# STM32WL31 register map
File version: 1.0
CPU: CM0+ r0p0, little endian, MPU, no FPU, 4 interrupt priority bits
Registers are 32-bit, read-write, reset 0x0 unless marked. A register's access mark holds for its fields unless they carry their own. Offsets are from the block's base; [hi:lo] are bit positions; {n}, {i} and the like mark numbered series.

## TIM2 — TIM2 address block description
Base 0x40002000
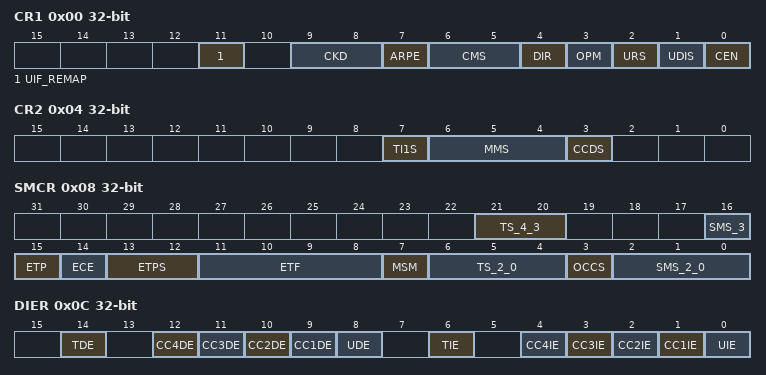
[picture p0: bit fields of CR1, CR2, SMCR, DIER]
0x00 CR1 (reset mask 0xF)
  [11] UIF_REMAP — UIFREMAP: UIF status bit remapping 0: No remapping. UIF status bit is not copied to TIMx_CNT register bit 31. 1: Remapping enabled. UIF status bit is copied to TIMx_CNT register bit 31.
  [9:8] CKD — CKD[1:0]: Clock division This bit-field indicates the division ratio between the timer clock (CK_INT) frequency and the dead-time and sampling clock (tDTS)used by the dead-time generators and the digital filters (TIx), 00: tDTS=tCK_INT 01: tDTS=2*tCK_INT 10: tDTS=4*tCK_INT 11: Reserved, do not program this value
  [7] ARPE — ARPE: Auto-reload preload enable 0: TIMx_ARR register is not buffered 1: TIMx_ARR register is buffered
  [6:5] CMS — CMS[1:0]: Center-aligned mode selection 00: Edge-aligned mode. The counter counts up or down depending on the direction bit (DIR). 01: Center-aligned mode 1. The counter counts up and down alternatively. Output compare interrupt flags of channels configured in output (CCxS=00 in TIMx_CCMRx register) are set only when the counter is counting down. 10: Center-aligned mode 2. The counter counts up and down alternatively. Output compare interrupt flags of channels configured in output (CCxS=00 in TIMx_CCMRx register) are set only when the counter is counting up. 11: Center-aligned mode 3. The counter counts up and down alternatively. Output compare interrupt flags of channels configured in output (CCxS=00 in TIMx_CCMRx register) are set both when the counter is counting up or down. Note: It is not allowed to switch from edge-aligned mode to center-aligned mode as long as the counter is enabled (CEN=1)
  [4] DIR — DIR: Direction 0: Counter used as upcounter 1: Counter used as downcounter Note: This bit is read only when the timer is configured in Center-aligned mode or Encoder mode.
  [3] OPM — OPM: One pulse mode 0: Counter is not stopped at update event. 1: Counter stops counting at the next update event (clearing the bit CEN)
  [2] URS — URS: Update request source This bit is set and cleared by software to select the UEV event sources. 0: Any of the following events generate an update interrupt or DMA request if enabled. These events can be: - Counter overflow/underflow - Setting the UG bit - Update generation through the slave mode controller 1: Only counter overflow/underflow generates an update interrupt or DMA request if enabled.
  [1] UDIS — UDIS: Update disable This bit is set and cleared by software to enable/disable UEV event generation. 0: UEV enabled. The Update (UEV) event is generated by one of the following events: - Counter overflow/underflow - Setting the UG bit - Update generation through the slave mode controller Buffered registers are then loaded with their preload values. 1: UEV disabled. The Update event is not generated, shadow registers keep their value (ARR, PSC, CCRx). However the counter and the prescaler are reinitialized if the UG bit is set or if a hardware reset is received from the slave mode controller.
  [0] CEN — CEN: Counter enable 0: Counter disabled 1: Counter enabled Note: External clock and gated mode can work only if the CEN bit has been previously set by software. However trigger mode can set the CEN bit automatically by hardware.
0x04 CR2 (reset mask 0xF)
  [7] TI1S — TI1S: TI1 selection 0: The TIMx_CH1 pin is connected to TI1 input. 1: The TIMx_CH1, CH2 and CH3 pins are connected to the TI1 input (XOR combination)
  [6:4] MMS — MMS[2:0]: Master mode selection These bits allow to select the information to be sent in master mode to slave timers for synchronization (TRGO). The combination is as follows: 000: Reset - the UG bit from the TIMx_EGR register is used as trigger output (TRGO). If the reset is generated by the trigger input (slave mode controller configured in reset mode) then the signal on TRGO is delayed compared to the actual reset. 001: Enable - the Counter enable signal, CNT_EN, is used as trigger output (TRGO). It is useful to start several timers at the same time or to control a window in which a slave timer is enabled. The Counter Enable signal is generated by a logic OR between CEN control bit and the trigger input when configured in gated mode. When the Counter Enable signal is controlled by the trigger input, there is a delay on TRGO, except if the master/slave mode is selected (see the MSM bit description in TIMx_SMCR register). 010: Update - The update event is selected as trigger output (TRGO). For instance a master timer can then be used as a prescaler for a slave timer. 011: Compare Pulse - The trigger output send a positive pulse when the CC1IF flag is to be set (even if it was already high), as soon as a capture or a compare match occurred. (TRGO) 100: Compare - OC1REF signal is used as trigger output (TRGO) 101: Compare - OC2REF signal is used as trigger output (TRGO) 110: Compare - OC3REF signal is used as trigger output (TRGO) 111: Compare - OC4REF signal is used as trigger output (TRGO) Note: The clock of the slave timer must be enabled prior to receive events from the master timer, and must not be changed on-the-fly while triggers are received from the master timer.
  [3] CCDS — CCDS: Capture/compare DMA selection 0: CCx DMA request sent when CCx event occurs 1: CCx DMA requests sent when update event occurs
0x08 SMCR reset not defined
  [21:20] TS_4_3 — Trigger selection. See TS_2_0_ description
  [16] SMS_3 — SMS[3]: Slave mode selection - bit 3 Refer to SMS description - bits2:0
  [15] ETP — ETP: External trigger polarity This bit selects whether ETR or ETR is used for trigger operations 0: ETR is non-inverted, active at high level or rising edge. 1: ETR is inverted, active at low level or falling edge.
  [14] ECE — ECE: External clock enable This bit enables External clock mode 2. 0: External clock mode 2 disabled 1: External clock mode 2 enabled. The counter is clocked by any active edge on the ETRF signal. Note: 1: Setting the ECE bit has the same effect as selecting external clock mode 1 with TRGI connected to ETRF (SMS=111 and TS=111). Note: 2: It is possible to simultaneously use external clock mode 2 with the following slave modes: reset mode, gated mode and trigger mode. Nevertheless, TRGI must not be connected to ETRF in this case (TS bits must not be 111). Note: 3: If external clock mode 1 and external clock mode 2 are enabled at the same time, the external clock input is ETRF.
  [13:12] ETPS — ETPS[1:0]: External trigger prescaler External trigger signal ETRP frequency must be at most 1/4 of TIMxCLK frequency. A prescaler can be enabled to reduce ETRP frequency. It is useful when inputting fast external clocks. 00: Prescaler OFF 01: ETRP frequency divided by 2 10: ETRP frequency divided by 4 11: ETRP frequency divided by 8
  [11:8] ETF — ETF[3:0]: External trigger filter This bit-field then defines the frequency used to sample ETRP signal and the length of the digital filter applied to ETRP. The digital filter is made of an event counter in which N events are needed to validate a transition on the output: 0000: No filter, sampling is done at fDTS 0001: fSAMPLING=fCK_INT, N=2 0010: fSAMPLING=fCK_INT, N=4 0011: fSAMPLING=fCK_INT, N=8 0100: fSAMPLING=fDTS/2, N=6 0101: fSAMPLING=fDTS/2, N=8 0110: fSAMPLING=fDTS/4, N=6 0111: fSAMPLING=fDTS/4, N=8 1000: fSAMPLING=fDTS/8, N=6 1001: fSAMPLING=fDTS/8, N=8 1010: fSAMPLING=fDTS/16, N=5 1011: fSAMPLING=fDTS/16, N=6 1100: fSAMPLING=fDTS/16, N=8 1101: fSAMPLING=fDTS/32, N=5 1110: fSAMPLING=fDTS/32, N=6 1111: fSAMPLING=fDTS/32, N=8
  [7] MSM — MSM: Master/Slave mode 0: No action 1: The effect of an event on the trigger input (TRGI) is delayed to allow a perfect synchronization between the current timer and its slaves (through TRGO). It is useful if we want to synchronize several timers on a single external event.
  [6:4] TS_2_0 — TS[4:0]: Trigger selection This bit-field selects the trigger input to be used to synchronize the counter. 00000: Internal Trigger 0 (ITR0) 00001: Internal Trigger 1 (ITR1) 00010: Internal Trigger 2 (ITR2) 00011: Internal Trigger 3 (ITR3) 00100: TI1 Edge Detector (TI1F_ED) 00101: Filtered Timer Input 1 (TI1FP1) 00110: Filtered Timer Input 2 (TI2FP2) 00111: External Trigger input (ETRF) Others: Reserved See Table Note:: TIM2 internal trigger connection on page 395 for more details on ITRx meaning for each Timer. Note: These bits must be changed only when they are not used (e.g. when SMS=000) to avoid wrong edge detections at the transition.
  [3] OCCS — OCCS: OCREF clear selection This bit is used to select the OCREF clear source. 0: OCREF_CLR_INT is connected to the OCREF_CLR input (stuck at 0 so no effect) 1: OCREF_CLR_INT is connected to ETRF
  [2:0] SMS_2_0 — SMS: Slave mode selection When external signals are selected the active edge of the trigger signal (TRGI) is linked to the polarity selected on the external input (see Input Control register and Control Register description. 0000: Slave mode disabled - if CEN = '1' then the prescaler is clocked directly by the internal clock. 0001: Encoder mode 1 - Counter counts up/down on TI2FP2 edge depending on TI1FP1 level. 0010: Encoder mode 2 - Counter counts up/down on TI1FP1 edge depending on TI2FP2 level. 0011: Encoder mode 3 - Counter counts up/down on both TI1FP1 and TI2FP2 edges depending on the level of the other input. 0100: Reset Mode - Rising edge of the selected trigger input (TRGI) reinitializes the counter and generates an update of the registers. 0101: Gated Mode - The counter clock is enabled when the trigger input (TRGI) is high. The counter stops (but is not reset) as soon as the trigger becomes low. Both start and stop of the counter are controlled. 0110: Trigger Mode - The counter starts at a rising edge of the trigger TRGI (but it is not reset). Only the start of the counter is controlled. 0111: External Clock Mode 1 - Rising edges of the selected trigger (TRGI) clock the counter. 1000: Combined reset + trigger mode - Rising edge of the selected trigger input (TRGI) reinitializes the counter, generates an update of the registers and starts the counter. Codes above 1000: Reserved. Note: The gated mode must not be used if TI1F_ED is selected as the trigger input (TS='100'). Indeed, TI1F_ED outputs 1 pulse for each transition on TI1F, whereas the gated mode checks the level of the trigger signal.
0x0C DIER (reset mask 0xF)
  [14] TDE — TDE: Trigger DMA request enable 0: Trigger DMA request disabled 1: Trigger DMA request enabled
  [n+8] CC{n}DE (n=1..4) — CC{n}DE: Capture/Compare {n} DMA request enable 0: CC{n} DMA request disabled 1: CC{n} DMA request enabled
  [8] UDE — UDE: Update DMA request enable 0: Update DMA request disabled 1: Update DMA request enabled
  [6] TIE — TIE: Trigger interrupt enable 0: Trigger interrupt disabled 1: Trigger interrupt enabled
  [4] CC4IE — CC4IE: Capture/Compare 4 interrupt enable 0: CC4 interrupt disabled 1: CC4 interrupt enabled
  [3] CC3IE — CC3IE: Capture/Compare 3 interrupt enable 0: CC3 interrupt disabled 1: CC3 interrupt enabled
  [2] CC2IE — CC2IE: Capture/Compare 2 interrupt enable 0: CC2 interrupt disabled 1: CC2 interrupt enabled
  [1] CC1IE — CC1IE: Capture/Compare 1 interrupt enable 0: CC1 interrupt disabled. 1: CC1 interrupt enabled
  [0] UIE — UIE: Update interrupt enable 0: Update interrupt disabled 1: Update interrupt enabled
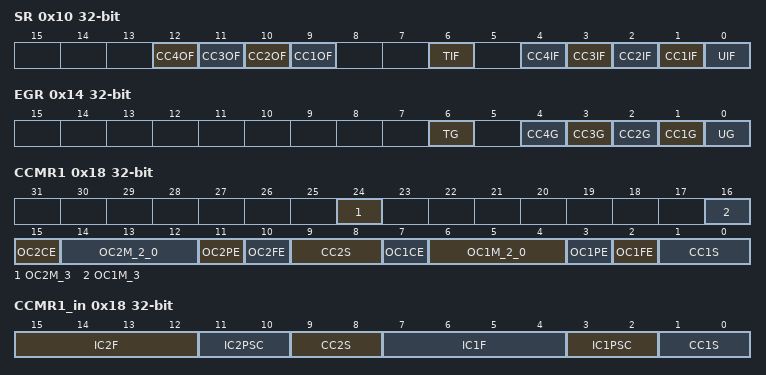
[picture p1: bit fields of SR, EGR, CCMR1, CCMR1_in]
0x10 SR (reset mask 0xF)
  [12] CC4OF — CC4OF: Capture/Compare 4 overcapture flag refer to CC1OF description
  [11] CC3OF — CC3OF: Capture/Compare 3 overcapture flag refer to CC1OF description
  [10] CC2OF — CC2OF: Capture/Compare 2 overcapture flag refer to CC1OF description
  [9] CC1OF — CC1OF: Capture/Compare 1 overcapture flag This flag is set by hardware only when the corresponding channel is configured in input capture mode. It is cleared by software by writing it to '0'. 0: No overcapture has been detected 1: The counter value has been captured in TIMx_CCR1 register while CC1IF flag was already set
  [6] TIF — TIF: Trigger interrupt flag This flag is set by hardware on trigger event (active edge detected on TRGI input when the slave mode controller is enabled in all modes but gated mode. It is set when the counter starts or stops when gated mode is selected. It is cleared by software.. 0: No trigger event occurred. 1: Trigger interrupt pending.
  [4] CC4IF — CC4IF: Capture/Compare 4 interrupt flag refer to CC1IF description
  [3] CC3IF — CC3IF: Capture/Compare 3 interrupt flag refer to CC1IF description
  [2] CC2IF — CC2IF: Capture/Compare 2 interrupt flag refer to CC1IF description
  [1] CC1IF — CC1IF: Capture/Compare 1 interrupt flag If channel CC1 is configured as output: This flag is set by hardware when the counter matches the compare value, with some exception in center-aligned mode (refer to the CMS bits in the TIMx_CR1 register description). It is cleared by software. 0: No match. 1: The content of the counter TIMx_CNT matches the content of the TIMx_CCR1 register. When the contents of TIMx_CCR1 are greater than the contents of TIMx_ARR, the CC1IF bit goes high on the counter overflow (in upcounting and up/down-counting modes) or underflow (in downcounting mode) If channel CC1 is configured as input: This bit is set by hardware on a capture. It is cleared by software or by reading the TIMx_CCR1 register. 0: No input capture occurred 1: The counter value has been captured in TIMx_CCR1 register (An edge has been detected on IC1 which matches the selected polarity)
  [0] UIF — UIF: Update interrupt flag This bit is set by hardware on an update event. It is cleared by software. 0: No update occurred. 1: Update interrupt pending. This bit is set by hardware when the registers are updated: At overflow regarding the repetition counter value (update if repetition counter = 0) and if the UDIS=0 in the TIMx_CR1 register. When CNT is reinitialized by software using the UG bit in TIMx_EGR register, if URS=0 and UDIS=0 in the TIMx_CR1 register.
0x14 EGR (reset mask 0xF)
  [6] TG wo — TG: Trigger generation This bit is set by software in order to generate an event, it is automatically cleared by hardware. 0: No action 1: The TIF flag is set in TIMx_SR register. Related interrupt can occur if enabled.
  [4] CC4G wo — CC4G: Capture/Compare 4 generation refer to CC1G description
  [3] CC3G wo — CC3G: Capture/Compare 3 generation refer to CC1G description
  [2] CC2G wo — CC2G: Capture/Compare 2 generation refer to CC1G description
  [1] CC1G wo — CC1G: Capture/Compare 1 generation This bit is set by software in order to generate an event, it is automatically cleared by hardware. 0: No action. 1: A capture/compare event is generated on channel 1: If channel CC1 is configured as output: CC1IF flag is set, Corresponding interrupt or DMA request is sent if enabled. If channel CC1 is configured as input: The current value of the counter is captured in TIMx_CCR1 register. The CC1IF flag is set, the corresponding interrupt or DMA request is sent if enabled. The CC1OF flag is set if the CC1IF flag was already high.
  [0] UG wo — UG: Update generation This bit can be set by software, it is automatically cleared by hardware. 0: No action. 1: Reinitialize the counter and generates an update of the registers. Note that the prescaler counter is cleared too (anyway the prescaler ratio is not affected).
0x18 CCMR1 (reset mask 0xF)
  [24] OC2M_3 — OC2M[3]: Output Compare 2 mode (bit 3)
  [16] OC1M_3 — OC1M[3]: Output Compare 1 mode (bit 3)
  [15] OC2CE — OC2CE: Output Compare 2 clear enable
  [14:12] OC2M_2_0 — OC2M[2:0]: Output Compare 2 mode
  [11] OC2PE — OC2PE: Output Compare 2 preload enable
  [10] OC2FE — OC2FE: Output Compare 2 fast enable
  [9:8] CC2S — CC2S[1:0]: Capture/Compare 2 selection This bit-field defines the direction of the channel (input/output) as well as the used input. 00: CC2 channel is configured as output 01: CC2 channel is configured as input, IC2 is mapped on TI2 10: CC2 channel is configured as input, IC2 is mapped on TI1 11: CC2 channel is configured as input, IC2 is mapped on TRC. This mode is working only if an internal trigger input is selected through the TS bit (TIMx_SMCR register) Note: CC2S bits are writable only when the channel is OFF (CC2E = '0' in TIMx_CCER).
  [7] OC1CE — OC1CE: Output Compare 1 Clear Enable 0: OC1Ref is not affected by the ETRF Input 1: OC1Ref is cleared as soon as a High level is detected on ETRF input
  [6:4] OC1M_2_0 — OC1M: Output Compare 1 mode These bits define the behavior of the output reference signal OC1REF from which OC1 and OC1N are derived. OC1REF is active high whereas OC1 and OC1N active level depends on CC1P and CC1NP bits. 0000: Frozen - The comparison between the output compare register TIMx_CCR1 and the counter TIMx_CNT has no effect on the outputs.(this mode is used to generate a timing base). 0001: Set channel 1 to active level on match. OC1REF signal is forced high when the counter TIMx_CNT matches the capture/compare register 1 (TIMx_CCR1). 0010: Set channel 1 to inactive level on match. OC1REF signal is forced low when the counter TIMx_CNT matches the capture/compare register 1 (TIMx_CCR1). 0011: Toggle - OC1REF toggles when TIMx_CNT=TIMx_CCR1. 0100: Force inactive level - OC1REF is forced low. 0101: Force active level - OC1REF is forced high. 0110: PWM mode 1 - In upcounting, channel 1 is active as long as TIMx_CNT TIMx_CCR1 else inactive. In downcounting, channel 1 is inactive (OC1REF='0') as long as TIMx_CNT>TIMx_CCR1 else active (OC1REF='1'). 0111: PWM mode 2 - In upcounting, channel 1 is inactive as long as TIMx_CNT TIMx_CCR1 else active. In downcounting, channel 1 is active as long as TIMx_CNT>TIMx_CCR1 else inactive. 1000: Retrigerrable OPM mode 1 - In up-counting mode, the channel is active until a trigger event is detected (on TRGI signal). Then, a comparison is performed as in PWM mode 1 and the channels becomes active again at the next update. In down-counting mode, the channel is inactive until a trigger event is detected (on TRGI signal). Then, a comparison is performed as in PWM mode 1 and the channels becomes inactive again at the next update. 1001: Retrigerrable OPM mode 2 - In up-counting mode, the channel is inactive until a trigger event is detected (on TRGI signal). Then, a comparison is performed as in PWM mode 2 and the channels becomes inactive again at the next update. In down-counting mode, the channel is active until a trigger event is detected (on TRGI signal). Then, a comparison is performed as in PWM mode 1 and the channels becomes active again at the next update. 1010: Reserved 1011: Reserved 1100: Combined PWM mode 1 - OC1REF has the same behavior as in PWM mode 1. OC1REFC is the logical OR between OC1REF and OC2REF. 1101: Combined PWM mode 2 - OC1REF has the same behavior as in PWM mode 2. OC1REFC is the logical AND between OC1REF and OC2REF 1110: Asymmetric PWM mode 1 - OC1REF has the same behavior as in PWM mode 1. OC1REFC outputs OC1REF when the counter is counting up, OC2REF when it is counting down. 1111: Asymmetric PWM mode 2 - OC1REF has the same behavior as in PWM mode 2. OC1REFC outputs OC1REF when the counter is counting up, OC2REF when it is counting down. Note: 1: These bits can not be modified as long as LOCK level 3 has been programmed (LOCK bits in TIMx_BDTR register) and CC1S='00' (the channel is configured in output). Note: 2: In PWM mode, the OCREF level changes only when the result of the comparison changes or when the output compare mode switches from 'frozen' mode to 'PWM' mode.
  [3] OC1PE — OC1PE: Output Compare 1 preload enable 0: Preload register on TIMx_CCR1 disabled. TIMx_CCR1 can be written at anytime, the new value is taken in account immediately. 1: Preload register on TIMx_CCR1 enabled. Read/Write operations access the preload register. TIMx_CCR1 preload value is loaded in the active register at each update event. Note: 1: These bits can not be modified as long as LOCK level 3 has been programmed (LOCK bits in TIMx_BDTR register) and CC1S='00' (the channel is configured in output). Note: 2: The PWM mode can be used without validating the preload register only in one pulse mode (OPM bit set in TIMx_CR1 register). Else the behavior is not guaranteed.
  [2] OC1FE — OC1FE: Output Compare 1 fast enable This bit is used to accelerate the effect of an event on the trigger in input on the CC output. 0: CC1 behaves normally depending on counter and CCR1 values even when the trigger is ON. The minimum delay to activate CC1 output when an edge occurs on the trigger input is 5 clock cycles. 1: An active edge on the trigger input acts like a compare match on CC1 output. Then, OC is set to the compare level independently of the result of the comparison. Delay to sample the trigger input and to activate CC1 output is reduced to 3 clock cycles. OC1FE acts only if the channel is configured in PWM1 or PWM2 mode.
  [1:0] CC1S — CC1S: Capture/Compare 1 Selection This bit-field defines the direction of the channel (input/output) as well as the used input. 00: CC1 channel is configured as output 01: CC1 channel is configured as input, IC1 is mapped on TI1 1x: Reserved Note: CC1S bits are writable only when the channel is OFF (CC1E = '0' in TIMx_CCER).
0x18 CCMR1_in (reset mask 0xF) (alternate view of CCMR1)
  [15:12] IC2F — IC2F: Input capture 2 filter
  [11:10] IC2PSC — IC2PSC[1:0]: Input capture 2 prescaler
  [9:8] CC2S — CC2S: Capture/Compare 2 selection This bit-field defines the direction of the channel (input/output) as well as the used input. 00: CC2 channel is configured as output 01: CC2 channel is configured as input, IC2 is mapped on TI2 10: CC2 channel is configured as input, IC2 is mapped on TI1 11: CC2 channel is configured as input, IC2 is mapped on TRC. This mode is working only if an internal trigger input is selected through TS bit (TIMx_SMCR register) Note: CC2S bits are writable only when the channel is OFF (CC2E = '0' in TIMx_CCER).
  [7:4] IC1F — Bits 7:4 IC1F[3:0]: Input capture 1 filter This bit-field defines the frequency used to sample TI1 input and the length of the digital filter applied to TI1. The digital filter is made of an event counter in which N events are needed to validate a transition on the output: 0000: No filter, sampling is done at fDTS 0001: fSAMPLING=fCK_INT, N=2 0010: fSAMPLING=fCK_INT, N=4 0011: fSAMPLING=fCK_INT, N=8 0100: fSAMPLING=fDTS/2, N= 0101: fSAMPLING=fDTS/2, N=8 0110: fSAMPLING=fDTS/4, N=6 0111: fSAMPLING=fDTS/4, N=8 1000: fSAMPLING=fDTS/8, N=6 1001: fSAMPLING=fDTS/8, N=8 1010: fSAMPLING=fDTS/16, N=5 1011: fSAMPLING=fDTS/16, N=6 1100: fSAMPLING=fDTS/16, N=8 1101: fSAMPLING=fDTS/32, N=5 1110: fSAMPLING=fDTS/32, N=6 1111: fSAMPLING=fDTS/32, N=8
  [3:2] IC1PSC — IC1PSC: Input capture 1 prescaler This bit-field defines the ratio of the prescaler acting on CC1 input (IC1). The prescaler is reset as soon as CC1E='0' (TIMx_CCER register). 00: no prescaler, capture is done each time an edge is detected on the capture input. 01: capture is done once every 2 events 10: capture is done once every 4 events 11: capture is done once every 8 events
  [1:0] CC1S — CC1S: Capture/Compare 1 Selection This bit-field defines the direction of the channel (input/output) as well as the used input. 00: CC1 channel is configured as output 01: CC1 channel is configured as input, IC1 is mapped on TI1 1x: Reserved Note: CC1S bits are writable only when the channel is OFF (CC1E = '0' in TIMx_CCER).
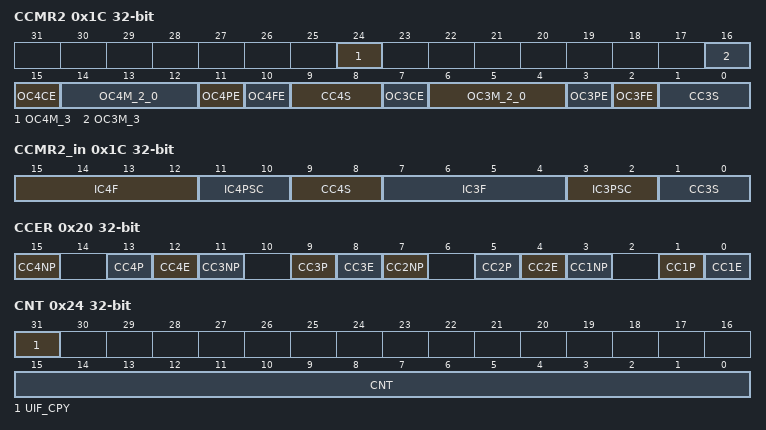
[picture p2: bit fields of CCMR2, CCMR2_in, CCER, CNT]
0x1C CCMR2 (reset mask 0xF)
  [24] OC4M_3 — OC4M[3]: Output Compare 4 mode (bit 3)
  [16] OC3M_3 — OC3M[3]: Output Compare 3 mode (bit 3)
  [15] OC4CE — OC4CE: Output Compare 4 clear enable
  [14:12] OC4M_2_0 — OC4M[2:0]: Output Compare 4 mode
  [11] OC4PE — OC4PE: Output Compare 4 preload enable
  [10] OC4FE — OC4FE: Output Compare 4 fast enable
  [9:8] CC4S — CC4S: Capture/Compare 4 selection This bit-field defines the direction of the channel (input/output) as well as the used input. 00: CC4 channel is configured as output 01: CC4 channel is configured as input, IC4 is mapped on TI4 10: CC4 channel is configured as input, IC4 is mapped on TI3 11: CC4 channel is configured as input, IC4 is mapped on TRC. This mode is working only if an internal trigger input is selected through TS bit (TIMx_SMCR register) Note: CC4S bits are writable only when the channel is OFF (CC4E = '0' in TIMx_CCER).
  [7] OC3CE — OC3CE: Output compare 3 clear enable
  [6:4] OC3M_2_0 — OC3M: Output compare 3 mode
  [3] OC3PE — OC3PE: Output compare 3 preload enable
  [2] OC3FE — OC3FE: Output compare 3 fast enable
  [1:0] CC3S — CC3S: Capture/Compare 3 selection This bit-field defines the direction of the channel (input/output) as well as the used input. 00: CC3 channel is configured as output 01: CC3 channel is configured as input, IC3 is mapped on TI3 10: CC3 channel is configured as input, IC3 is mapped on TI4 11: CC3 channel is configured as input, IC3 is mapped on TRC. This mode is working only if an internal trigger input is selected through TS bit (TIMx_SMCR register) Note: CC3S bits are writable only when the channel is OFF (CC3E = '0' in TIMx_CCER).
0x1C CCMR2_in (reset mask 0xF) (alternate view of CCMR2)
  [15:12] IC4F — IC4F: Input capture 4 filter
  [11:10] IC4PSC — IC4PSC: Input capture 4 prescaler
  [9:8] CC4S — CC4S: Capture/Compare 4 selection This bit-field defines the direction of the channel (input/output) as well as the used input. 00: CC4 channel is configured as output 01: CC4 channel is configured as input, IC4 is mapped on TI4 10: CC4 channel is configured as input, IC4 is mapped on TI3 11: CC4 channel is configured as input, IC4 is mapped on TRC. This mode is working only if an internal trigger input is selected through TS bit (TIMx_SMCR register) Note: CC4S bits are writable only when the channel is OFF (CC4E = '0' in TIMx_CCER).
  [7:4] IC3F — IC3F: Input capture 3 filter
  [3:2] IC3PSC — IC3PSC: Input capture 3 prescaler
  [1:0] CC3S — CC3S: Capture/compare 3 selection This bit-field defines the direction of the channel (input/output) as well as the used input. 00: CC3 channel is configured as output 01: CC3 channel is configured as input, IC3 is mapped on TI3 10: CC3 channel is configured as input, IC3 is mapped on TI4 11: CC3 channel is configured as input, IC3 is mapped on TRC. This mode is working only if an internal trigger input is selected through TS bit (TIMx_SMCR register) Note: CC3S bits are writable only when the channel is OFF (CC3E = '0' in TIMx_CCER).
0x20 CCER (reset mask 0xF)
  [15] CC4NP — CC4NP: Capture/Compare 4 Complementary output Polarity. This field is not used in Blue51. Not available in IUM refer to CC1NP description
  [13] CC4P — CC4P: Capture/Compare 4 output polarity refer to CC1P description
  [12] CC4E — CC4E: Capture/Compare 4 output enable refer to CC1E description
  [11] CC3NP — CC3NP: Capture/Compare 3 Complementary output Polarity. This field is not used in Blue51. Not available in IUM refer to CC1NP description
  [9] CC3P — CC3P: Capture/Compare 3 output polarity refer to CC1P description
  [8] CC3E — CC3E: Capture/Compare 3 output enable refer to CC1E description
  [7] CC2NP — CC2NP: Capture/Compare 2 Complementary output Polarity. This field is not used in Blue51. Not available in IUM refer to CC1NP description
  [5] CC2P — CC2P: Capture/Compare 2 output polarity refer to CC1P description
  [4] CC2E — CC2E: Capture/Compare 2 output enable refer to CC1E description
  [3] CC1NP — CC1NP: Capture/Compare 1 Complementary output Polarity. This field is not used in Blue51. Not available in IUM Note: This bit is no longer writeable as soon as LOCK level 2 or 3 has been programmed (LOCK bits in GPT_BDTR register) and CC1S='00' (the channel is configured in output).
    0=OC1N active high; 1=OC1N active low
  [1] CC1P — CC1P: Capture/Compare 1 output polarity CC1 channel configured as output: 0: OC1 active high 1: OC1 active low CC1 channel configured as input: The CC1NP/CC1P bits select the polarity of TI1FP1 for trigger or capture operations. 00: Non-inverted/rising edge. The circuit is sensitive to TIxFP1 rising edge (capture or trigger operations in reset, external clock or trigger mode), TIxFP1 is not inverted (trigger operation in gated mode). 01: Inverted/falling edge. The circuit is sensitive to TIxFP1 falling edge (capture or trigger operations in reset, external clock or trigger mode), TIxFP1 is inverted (trigger operation in gated mode. 10: Reserved, do not use this configuration. 11: Non-inverted/both edges. The circuit is sensitive to both TIxFP1 rising and falling edges (capture or trigger operations in reset, external clock or trigger mode), TIxFP1 is not inverted (trigger operation in gated mode). Note: 1. This bit is not writable as soon as LOCK level 2 or 3 has been programmed (LOCK bits in TIMx_BDTR register). 2. On channels that have a complementary output, this bit is preloaded. If the CCPC bit is set in the TIMx_CR2 register then the CC1P active bit takes the new value from the preloaded bit only when a Commutation event is generated.
  [0] CC1E — CC1E: Capture/Compare 1 output enable CC1 channel configured as output: 0: Off - OC1 is not active. OC1 level is then function of MOE, OSSI, OSSR, OIS1, OIS1N and CC1NE bits. 1: On - OC1 signal is output on the corresponding output pin depending on MOE, OSSI, OSSR, OIS1, OIS1N and CC1NE bits. CC1 channel configured as input: This bit determines if a capture of the counter value can actually be done into the input capture/compare register 1 (TIMx_CCR1) or not. 0: Capture disabled 1: Capture enabled
0x24 CNT (reset mask 0xF)
  [31] UIF_CPY ro — UIFCPY: UIF Copy This bit is a read-only copy of the UIF bit of the TIMx_ISR register. If the UIFREMAP bit in TIMx_CR1 is reset, bit 31 is reserved and read as 0.
  [15:0] CNT — CNT[15:0]: Counter value
0x28 PSC (reset mask 0xF)
  [15:0] PSC — PSC[15:0]: Prescaler value The counter clock frequency (CK_CNT) is equal to fCK_PSC / (PSC[15:0] + 1). PSC contains the value to be loaded in the active prescaler register at each update event (including when the counter is cleared through UG bit of TIMx_EGR register or through trigger controller when configured in 'reset mode').
0x2C ARR reset 0xFFFF
  [15:0] ARR — ARR[15:0]: Prescaler value ARR is the value to be loaded in the actual auto-reload register. Refer to the Section 22.3.1: Time-base unit on page 418 for more details about ARR update and behavior. The counter is blocked while the auto-reload value is null.
0x30 RCR (reset mask 0xF)
  [7:0] REP — REP[7:0]: Repetition counter value These bits allow the user to set-up the update rate of the compare registers (i.e. periodic transfers from preload to active registers) when preload registers are enable, as well as the update interrupt generation rate, if this interrupt is enable. Each time the REP_CNT related downcounter reaches zero, an update event is generated and it restarts counting from REP value. As REP_CNT is reloaded with REP value only at the repetition update event U_RC, any write to the TIMx_RCR register is not taken in account until the next repetition update event. It means in PWM mode (REP+1) corresponds to the number of PWM periods in edge-aligned mode.
{0x30+4i} CCR{i} (reset mask 0xF) (i=1..4)
  [15:0] CCR{i} — CCR{i}[15:0]: Capture/Compare {i} value If channel CC{i} is configured as output: CCR{i} is the value to be loaded in the actual capture/compare {i} register (preload value). It is loaded permanently if the preload feature is not selected in the TIMx_CCMR{i} register (bit OC{i}PE). Else the preload value is copied in the active capture/compare {i} register when an update event occurs. The active capture/compare register contains the value to be compared to the counter TIMx_CNT and signaled on OC{i} output. If channel CC{i} is configured as input: CCR{i} is the counter value transferred by the last input capture {i} event (IC{i}).
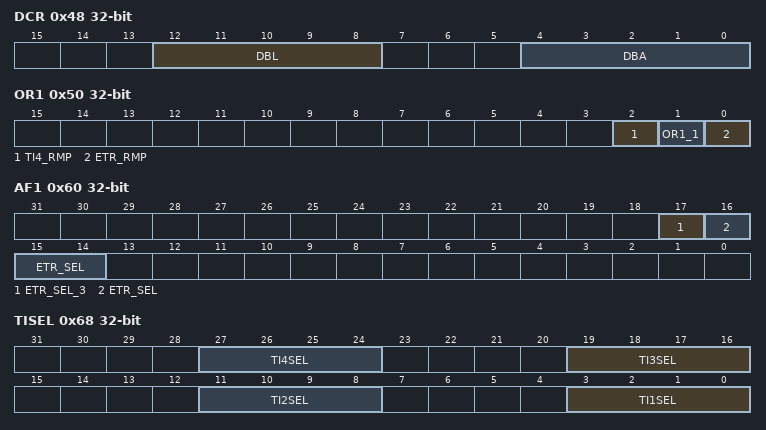
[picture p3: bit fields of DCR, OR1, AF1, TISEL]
0x48 DCR (reset mask 0xF)
  [12:8] DBL — DBL[4:0]: DMA burst length This 5-bit field defines the length of DMA transfers (the timer recognizes a burst transfer when a read or a write access is done to the TIMx_DMAR address), i.e. the number of transfers. Transfers can be in half-words or in bytes (see example below). 00000: 1 transfer, 00001: 2 transfers, 00010: 3 transfers, ... 10001: 18 transfers.
  [4:0] DBA — DBA[4:0]: DMA base address This 5-bit field defines the base-address for DMA transfers (when read/write access are done through the TIMx_DMAR address). DBA is defined as an offset starting from the address of the TIMx_CR1 register. Example: 00000: TIMx_CR1, 00001: TIMx_CR2, 00010: Reserved, ... Example: Let us consider the following transfer: DBL = 7 transfers and DBA = TIMx_CR1. In this case the transfer is done to/from 7 registers starting from the TIMx_CR1 address.
0x4C DMAR (reset mask 0xF)
  [15:0] DMAB — DMAB[15:0]: DMA register for burst accesses A read or write operation to the DMAR register accesses the register located at the address (TIM2_CR1 address) + (DBA + DMA index) x 4 where TIM2_CR1 address is the address of the control register 1, DBA is the DMA base address configured in TIM2_DCR register, DMA index is automatically controlled by the DMA transfer, and ranges from 0 to DBL (DBL configured in TIM2_DCR).
0x50 OR1
  [2] TI4_RMP — TI4_RMP: Input capture 4 remap 0: TIM2 input capture 4 is connected to I/O 1: TIM2 input capture 4 is connected to COMP1-OUT
  [1] OR1_1 — This field is not used in Blue51. Not available in IUM
  [0] ETR_RMP — ETR_RMP: ETR remapping capability 0: TIMx_ETR is not connected to ADC AWD (must be selected when the ETR comes from the ETR input pin) 1: TIMx_ETR is connected to ADC AWD Note: ADC AWD source is 'ORed' with the TIMx_ETR input signals. When ADC AWD is used, it is necessary to make sure that the corresponding TIMx_ETR input pin is not enabled in the alternate function controller.
0x60 AF1 (reset mask 0xF)
  [17] ETR_SEL_3 — ETRSEL[2:0]: External trigger source selection This field is not used in Blue51. Not available in IUM
  [16:14] ETR_SEL — ETRSEL[2:0]: External trigger source selection 000: TIMx External trigger legacy mode 001: TIMx External trigger source select COMP1_OUT Other: Reserved Note: These bits can't be modified as long as LOCK level 1 has been programmed (LOCK bits in TIMx_BDTR register)
0x68 TISEL
  [8n-5:8n-8] TI{n}SEL (n=1..4) — TI{n}SEL[3:0]: selects TI{n}[0] to TI{n}[15] input 0000: TIMx_CH{n} input Others: Reserved
